# MCU_I3C1_S_ECC_AGGR_CFG register map
Vendor: Texas Instruments
Peripheral module from a debugger description file (folder J721S2).
Registers are 32-bit, access not given, reset 0x0 unless marked. A register's access mark holds for its fields unless they carry their own. Offsets are as the file gives them; lines under a group give offsets from that group; [hi:lo] are bit positions; {n}, {i} and the like mark numbered series; 'fields as' and 'values as' point back to an identical list; <NAME> marks a mode.

## MCU_I3C1_S_ECC_AGGR_CFG
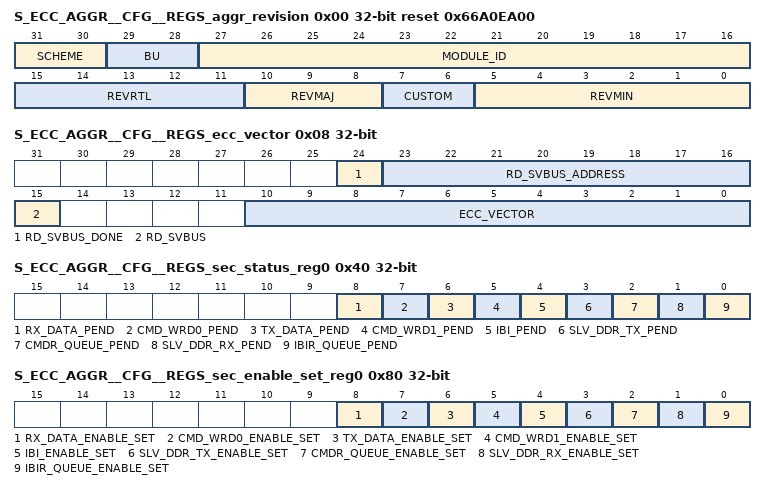
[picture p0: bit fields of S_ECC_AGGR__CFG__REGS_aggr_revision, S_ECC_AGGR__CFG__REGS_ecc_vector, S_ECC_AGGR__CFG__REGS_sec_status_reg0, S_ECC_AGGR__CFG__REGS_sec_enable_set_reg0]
0x00 S_ECC_AGGR__CFG__REGS_aggr_revision ro reset 0x66A0EA00 — Revision parameters
  [31:30] SCHEME
  [29:28] BU
  [27:16] MODULE_ID
  [15:11] REVRTL — RTL version
  [10:8] REVMAJ — Major version
  [7:6] CUSTOM — Custom version
  [5:0] REVMIN — Minor version
0x08 S_ECC_AGGR__CFG__REGS_ecc_vector — ECC Vector Register
  [24] RD_SVBUS_DONE — Status to indicate if read on serial VBUS is complete, write of any value will clear this bit. (access R/W1TC)
  [23:16] RD_SVBUS_ADDRESS rw — Read address
  [15] RD_SVBUS — Write 1 to trigger a read on the serial VBUS (access R/W1TS)
  [10:0] ECC_VECTOR rw — Value written to select the corresponding ECC RAM for control or status
0x0C S_ECC_AGGR__CFG__REGS_misc_status ro reset 0x9 — Misc Status
  [10:0] NUM_RAMS — Indicates the number of RAMS serviced by the ECC aggregator
0x10 S_ECC_AGGR__CFG__REGS_reserved_svbus rw — Reference other documents that contain the ECC RAM wrapper and EDC controller serial vbus register sets.
  [31:0] DATA — Serial VBUS register data
0x3C S_ECC_AGGR__CFG__REGS_sec_eoi_reg — EOI Register
  [0] EOI_WR — EOI Register (access R/W1TS)
0x40 S_ECC_AGGR__CFG__REGS_sec_status_reg0 — Interrupt Status Register 0
  [8] RX_DATA_PEND — Interrupt Pending Status for rx_data_pend (access R/W1TS)
  [7] CMD_WRD0_PEND — Interrupt Pending Status for cmd_wrd0_pend (access R/W1TS)
  [6] TX_DATA_PEND — Interrupt Pending Status for tx_data_pend (access R/W1TS)
  [5] CMD_WRD1_PEND — Interrupt Pending Status for cmd_wrd1_pend (access R/W1TS)
  [4] IBI_PEND — Interrupt Pending Status for ibi_pend (access R/W1TS)
  [3] SLV_DDR_TX_PEND — Interrupt Pending Status for slv_ddr_tx_pend (access R/W1TS)
  [2] CMDR_QUEUE_PEND — Interrupt Pending Status for cmdr_queue_pend (access R/W1TS)
  [1] SLV_DDR_RX_PEND — Interrupt Pending Status for slv_ddr_rx_pend (access R/W1TS)
  [0] IBIR_QUEUE_PEND — Interrupt Pending Status for ibir_queue_pend (access R/W1TS)
0x80 S_ECC_AGGR__CFG__REGS_sec_enable_set_reg0 — Interrupt Enable Set Register 0
  [8] RX_DATA_ENABLE_SET — Interrupt Enable Set Register for rx_data_pend (access R/W1TS)
  [7] CMD_WRD0_ENABLE_SET — Interrupt Enable Set Register for cmd_wrd0_pend (access R/W1TS)
  [6] TX_DATA_ENABLE_SET — Interrupt Enable Set Register for tx_data_pend (access R/W1TS)
  [5] CMD_WRD1_ENABLE_SET — Interrupt Enable Set Register for cmd_wrd1_pend (access R/W1TS)
  [4] IBI_ENABLE_SET — Interrupt Enable Set Register for ibi_pend (access R/W1TS)
  [3] SLV_DDR_TX_ENABLE_SET — Interrupt Enable Set Register for slv_ddr_tx_pend (access R/W1TS)
  [2] CMDR_QUEUE_ENABLE_SET — Interrupt Enable Set Register for cmdr_queue_pend (access R/W1TS)
  [1] SLV_DDR_RX_ENABLE_SET — Interrupt Enable Set Register for slv_ddr_rx_pend (access R/W1TS)
  [0] IBIR_QUEUE_ENABLE_SET — Interrupt Enable Set Register for ibir_queue_pend (access R/W1TS)
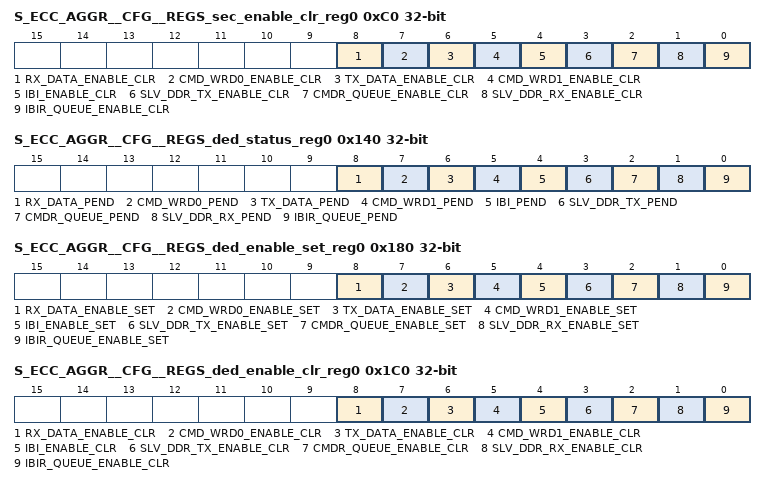
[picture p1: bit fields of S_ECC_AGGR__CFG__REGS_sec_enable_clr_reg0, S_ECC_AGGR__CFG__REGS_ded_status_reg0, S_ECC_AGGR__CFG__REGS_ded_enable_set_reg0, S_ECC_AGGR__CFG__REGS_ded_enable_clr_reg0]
0xC0 S_ECC_AGGR__CFG__REGS_sec_enable_clr_reg0 — Interrupt Enable Clear Register 0
  [8] RX_DATA_ENABLE_CLR — Interrupt Enable Clear Register for rx_data_pend (access R/W1TC)
  [7] CMD_WRD0_ENABLE_CLR — Interrupt Enable Clear Register for cmd_wrd0_pend (access R/W1TC)
  [6] TX_DATA_ENABLE_CLR — Interrupt Enable Clear Register for tx_data_pend (access R/W1TC)
  [5] CMD_WRD1_ENABLE_CLR — Interrupt Enable Clear Register for cmd_wrd1_pend (access R/W1TC)
  [4] IBI_ENABLE_CLR — Interrupt Enable Clear Register for ibi_pend (access R/W1TC)
  [3] SLV_DDR_TX_ENABLE_CLR — Interrupt Enable Clear Register for slv_ddr_tx_pend (access R/W1TC)
  [2] CMDR_QUEUE_ENABLE_CLR — Interrupt Enable Clear Register for cmdr_queue_pend (access R/W1TC)
  [1] SLV_DDR_RX_ENABLE_CLR — Interrupt Enable Clear Register for slv_ddr_rx_pend (access R/W1TC)
  [0] IBIR_QUEUE_ENABLE_CLR — Interrupt Enable Clear Register for ibir_queue_pend (access R/W1TC)
0x13C S_ECC_AGGR__CFG__REGS_ded_eoi_reg — EOI Register
  [0] EOI_WR — EOI Register (access R/W1TS)
0x140 S_ECC_AGGR__CFG__REGS_ded_status_reg0 — Interrupt Status Register 0
  fields as S_ECC_AGGR__CFG__REGS_sec_status_reg0
0x180 S_ECC_AGGR__CFG__REGS_ded_enable_set_reg0 — Interrupt Enable Set Register 0
  fields as S_ECC_AGGR__CFG__REGS_sec_enable_set_reg0
0x1C0 S_ECC_AGGR__CFG__REGS_ded_enable_clr_reg0 — Interrupt Enable Clear Register 0
  fields as S_ECC_AGGR__CFG__REGS_sec_enable_clr_reg0
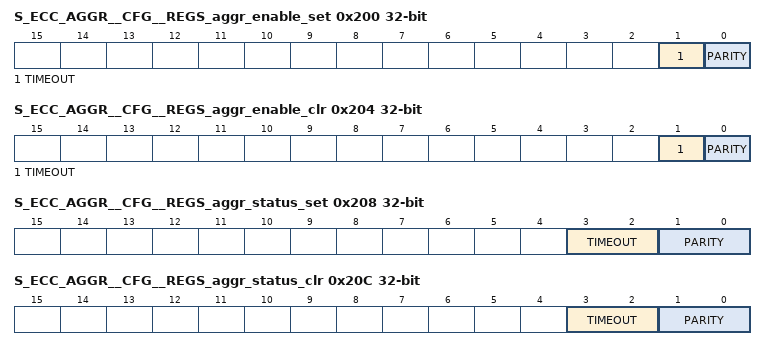
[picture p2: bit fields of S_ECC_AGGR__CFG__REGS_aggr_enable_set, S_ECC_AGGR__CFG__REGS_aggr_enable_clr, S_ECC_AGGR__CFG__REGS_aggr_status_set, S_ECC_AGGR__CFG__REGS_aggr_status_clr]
0x200 S_ECC_AGGR__CFG__REGS_aggr_enable_set — AGGR interrupt enable set Register
  [1] TIMEOUT — interrupt enable set for svbus timeout errors (access R/W1TS)
  [0] PARITY — interrupt enable set for parity errors (access R/W1TS)
0x204 S_ECC_AGGR__CFG__REGS_aggr_enable_clr — AGGR interrupt enable clear Register
  [1] TIMEOUT — interrupt enable clear for svbus timeout errors (access R/W1TC)
  [0] PARITY — interrupt enable clear for parity errors (access R/W1TC)
0x208 S_ECC_AGGR__CFG__REGS_aggr_status_set — AGGR interrupt status set Register
  [3:2] TIMEOUT — interrupt status set for svbus timeout errors (access R/WI)
  [1:0] PARITY — interrupt status set for parity errors (access R/WI)
0x20C S_ECC_AGGR__CFG__REGS_aggr_status_clr — AGGR interrupt status clear Register
  [3:2] TIMEOUT — interrupt status clear for svbus timeout errors (access R/WD)
  [1:0] PARITY — interrupt status clear for parity errors (access R/WD)
